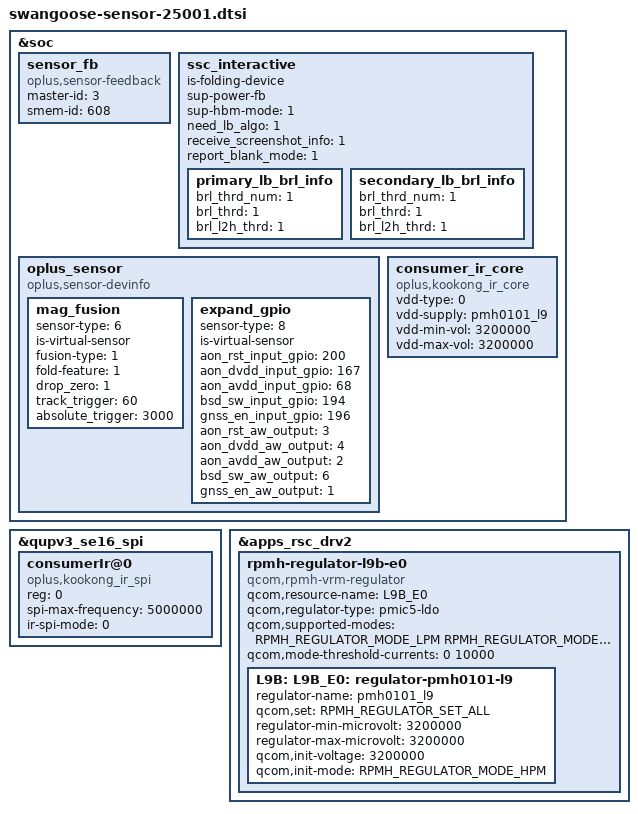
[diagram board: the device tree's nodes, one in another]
/**********************************************************************************
 * Copyright (c)  2022-2024  Guangdong oplus Mobile Comm Corp., Ltd
 * Description: oplus sensor dtsi
 *
 * Version: 1.0
 * Date: 2022-07-04
 *
 * ------------------------------ Revision History: --------------------------------
 * <version>         <date>        <author>                <desc>
 ***********************************************************************************/
#include <dt-bindings/regulator/qcom,rpmh-regulator-levels.h>
&soc {
    //#ifdef OPLUS_FEATURE_SENSOR_SMEM
sensor_fb: sensor_fb {
               compatible = "oplus,sensor-feedback";
               master-id  = <3>;
               smem-id    = <608>;
           };
           ssc_interactive {
               is-folding-device;
               sup-power-fb;
               sup-hbm-mode = <1>;
               need_lb_algo = <1>;
               receive_screenshot_info = <1>;
               report_blank_mode = <1>;

               primary_lb_brl_info {
                    brl_thrd_num = <1>;
                    brl_thrd = <1>;
                    brl_l2h_thrd = <1>;
               };
               secondary_lb_brl_info {
                   brl_thrd_num = <1>;
                   brl_thrd = <1>;
                   brl_l2h_thrd = <1>;
               };
           };
           oplus_sensor {
               compatible = "oplus,sensor-devinfo";
               /*virtual sensor*/
               mag_fusion {
                   sensor-type = <6>;//OPLUS_MAG_FUSION
                   is-virtual-sensor;
                   fusion-type = <1>;//AKM_FUSION
                   fold-feature = <1>;
                   drop_zero = <1>;
                   track_trigger = <60>;
                   absolute_trigger = <3000>;
               };
               expand_gpio {
                  sensor-type = <8>;//OPLUS_EXPAND_GPIO
                  is-virtual-sensor;
                  aon_rst_input_gpio = <200>;//read adsp pin interrupt
                  aon_dvdd_input_gpio = <167>;
                  aon_avdd_input_gpio = <68>;
                  bsd_sw_input_gpio = <194>;
                  gnss_en_input_gpio = <196>;

                  aon_rst_aw_output = <3>;//write aw95124 response pin
                  aon_dvdd_aw_output = <4>;
                  aon_avdd_aw_output = <2>;
                  bsd_sw_aw_output = <6>;
                  gnss_en_aw_output = <1>;
               };
           };
           consumer_ir_core {
               compatible = "oplus,kookong_ir_core";
               status = "okay";
               vdd-type = <0>; /*0: internal LDO , 1: external LOD*/
               vdd-supply = <&pmh0101_l9>;
               vdd-min-vol = <3200000>;
               vdd-max-vol = <3200000>;
           };
           //#endif /*OPLUS_FEATURE_SENSOR_SMEM*/
};

//add for oplus consumerIr SPI mode
&qupv3_se16_spi{
    status = "ok";
    consumerIr@0 {
        compatible = "oplus,kookong_ir_spi";
        reg = <0>;
        status = "ok";

        spi-max-frequency = <5000000>;    /*4800000,9600000,15000000,19200000*/
        ir-spi-mode = <0>;
    };
};

&apps_rsc_drv2{
    rpmh-regulator-l9b-e0 {
        compatible = "qcom,rpmh-vrm-regulator";
        qcom,resource-name = "L9B_E0";
        qcom,regulator-type = "pmic5-ldo";
        qcom,supported-modes =
            <RPMH_REGULATOR_MODE_LPM
             RPMH_REGULATOR_MODE_HPM>;
        qcom,mode-threshold-currents = <0 10000>;

        L9B: L9B_E0: pmh0101_l9: regulator-pmh0101-l9 {
            regulator-name = "pmh0101_l9";
            qcom,set = <RPMH_REGULATOR_SET_ALL>;
            regulator-min-microvolt = <3200000>;
            regulator-max-microvolt = <3200000>;
            qcom,init-voltage = <3200000>;
            qcom,init-mode = <RPMH_REGULATOR_MODE_HPM>;
        };
    };
};

